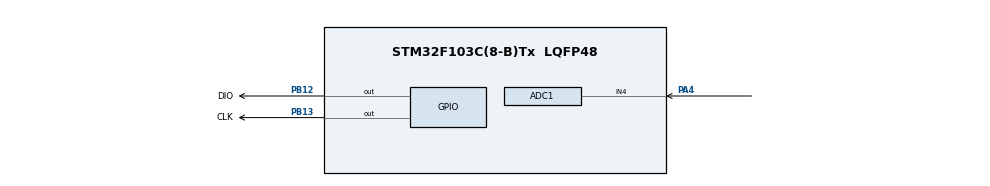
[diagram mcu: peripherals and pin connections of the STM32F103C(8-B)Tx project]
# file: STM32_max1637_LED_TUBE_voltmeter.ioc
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ADC1.Channel-12\#ChannelRegularConversion=ADC_CHANNEL_4
ADC1.NbrOfConversionFlag=1
ADC1.Rank-12\#ChannelRegularConversion=1
ADC1.SamplingTime-12\#ChannelRegularConversion=ADC_SAMPLETIME_1CYCLE_5
ADC1.master=1
Mcu.Family=STM32F1
Mcu.Name=STM32F103C(8-B)Tx
Mcu.Package=LQFP48
NVIC.PriorityGroup=NVIC_PRIORITYGROUP_4
PA13.Mode=Serial_Wire
PA13.Signal=SYS_JTMS-SWDIO
PA14.Mode=Serial_Wire
PA14.Signal=SYS_JTCK-SWCLK
PA4.Signal=ADCx_IN4
PB12.GPIO_Label=DIO
PB12.Signal=GPIO_Output
PB13.GPIO_Label=CLK
PB13.Signal=GPIO_Output
ProjectManager.HeapSize=0x200
ProjectManager.StackSize=0x400
ProjectManager.TargetToolchain=Makefile
RCC.APB1CLKDivider=RCC_HCLK_DIV4
RCC.APB1Freq_Value=2000000
RCC.APB1TimFreq_Value=4000000
RCC.APB2Freq_Value=8000000
RCC.APB2TimFreq_Value=8000000
SH.ADCx_IN4.0=ADC1_IN4,IN4

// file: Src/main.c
/**
  ******************************************************************************
  * File Name          : main.c
  * Description        : Main program body
  ******************************************************************************
  ** This notice applies to any and all portions of this file
  * that are not between comment pairs USER CODE BEGIN and
  * USER CODE END. Other portions of this file, whether
  * inserted by the user or by software development tools
  * are owned by their respective copyright owners.
  *
  * COPYRIGHT(c) 2017 STMicroelectronics
  *
  * Redistribution and use in source and binary forms, with or without modification,
  * are permitted provided that the following conditions are met:
  *   1. Redistributions of source code must retain the above copyright notice,
  *      this list of conditions and the following disclaimer.
  *   2. Redistributions in binary form must reproduce the above copyright notice,
  *      this list of conditions and the following disclaimer in the documentation
  *      and/or other materials provided with the distribution.
  *   3. Neither the name of STMicroelectronics nor the names of its contributors
  *      may be used to endorse or promote products derived from this software
  *      without specific prior written permission.
  *
  * THIS SOFTWARE IS PROVIDED BY THE COPYRIGHT HOLDERS AND CONTRIBUTORS "AS IS"
  * AND ANY EXPRESS OR IMPLIED WARRANTIES, INCLUDING, BUT NOT LIMITED TO, THE
  * IMPLIED WARRANTIES OF MERCHANTABILITY AND FITNESS FOR A PARTICULAR PURPOSE ARE
  * DISCLAIMED. IN NO EVENT SHALL THE COPYRIGHT HOLDER OR CONTRIBUTORS BE LIABLE
  * FOR ANY DIRECT, INDIRECT, INCIDENTAL, SPECIAL, EXEMPLARY, OR CONSEQUENTIAL
  * DAMAGES (INCLUDING, BUT NOT LIMITED TO, PROCUREMENT OF SUBSTITUTE GOODS OR
  * SERVICES; LOSS OF USE, DATA, OR PROFITS; OR BUSINESS INTERRUPTION) HOWEVER
  * CAUSED AND ON ANY THEORY OF LIABILITY, WHETHER IN CONTRACT, STRICT LIABILITY,
  * OR TORT (INCLUDING NEGLIGENCE OR OTHERWISE) ARISING IN ANY WAY OUT OF THE USE
  * OF THIS SOFTWARE, EVEN IF ADVISED OF THE POSSIBILITY OF SUCH DAMAGE.
  *
  ******************************************************************************
  */
#include "main.h"
#include "stm32f1xx_hal.h"

/* USER CODE BEGIN Includes */
#include "1637.h"
#include "main.h"

#define PORT GPIOB
// #define DIO_Pin GPIO_PIN_12
// #define CLK_Pin GPIO_PIN_13

/* USER CODE END Includes */

ADC_HandleTypeDef hadc1;

/* USER CODE BEGIN PV */
/* Private variables ---------------------------------------------------------*/
uint32_t adcResult = 0;
long num;
uint8_t adc_counter;
long display;
/* USER CODE END PV */

void SystemClock_Config(void);
static void MX_GPIO_Init(void);
static void MX_ADC1_Init(void);

/* USER CODE BEGIN PFP */
/* Private function prototypes -----------------------------------------------*/

/* USER CODE END PFP */

int main(void)
{

  /* MCU Configuration----------------------------------------------------------*/

  /* Reset of all peripherals, Initializes the Flash interface and the Systick. */
  HAL_Init();

  /* Configure the system clock */
  SystemClock_Config();

  /* Initialize all configured peripherals */
  MX_GPIO_Init();
  MX_ADC1_Init();

  /* Infinite loop */
  while (1)
  {

  /* USER CODE BEGIN 3 */
    HAL_ADC_Start(&hadc1);
    HAL_ADC_PollForConversion(&hadc1, 100);
    adcResult += HAL_ADC_GetValue(&hadc1);
    adc_counter++; // Увеличиваем счетчик измерений
    if(adc_counter > 5) // Если количество измерений больше N
    {
      display = adcResult/adc_counter/1.246; // Вычисляем среднее значение
      adc_counter = 0; // Обнуляем счетчик измерений
      adcResult = 0; // Обнуляем значение
      HAL_ADC_Stop(&hadc1);
    }
    indication(display);
    HAL_Delay(20);
  }
  /* USER CODE END 3 */

}

/** System Clock Configuration
*/
void SystemClock_Config(void)
{

  RCC_OscInitTypeDef RCC_OscInitStruct;
  RCC_ClkInitTypeDef RCC_ClkInitStruct;
  RCC_PeriphCLKInitTypeDef PeriphClkInit;

    /**Initializes the CPU, AHB and APB busses clocks
    */
  RCC_OscInitStruct.OscillatorType = RCC_OSCILLATORTYPE_HSI;
  RCC_OscInitStruct.HSIState = RCC_HSI_ON;
  RCC_OscInitStruct.HSICalibrationValue = 16;
  RCC_OscInitStruct.PLL.PLLState = RCC_PLL_NONE;
  if (HAL_RCC_OscConfig(&RCC_OscInitStruct) != HAL_OK)
  {
    _Error_Handler(__FILE__, __LINE__);
  }

    /**Initializes the CPU, AHB and APB busses clocks
    */
  RCC_ClkInitStruct.ClockType = RCC_CLOCKTYPE_HCLK|RCC_CLOCKTYPE_SYSCLK
                              |RCC_CLOCKTYPE_PCLK1|RCC_CLOCKTYPE_PCLK2;
  RCC_ClkInitStruct.SYSCLKSource = RCC_SYSCLKSOURCE_HSI;
  RCC_ClkInitStruct.AHBCLKDivider = RCC_SYSCLK_DIV1;
  RCC_ClkInitStruct.APB1CLKDivider = RCC_HCLK_DIV4;
  RCC_ClkInitStruct.APB2CLKDivider = RCC_HCLK_DIV1;

  if (HAL_RCC_ClockConfig(&RCC_ClkInitStruct, FLASH_LATENCY_0) != HAL_OK)
  {
    _Error_Handler(__FILE__, __LINE__);
  }

  PeriphClkInit.PeriphClockSelection = RCC_PERIPHCLK_ADC;
  PeriphClkInit.AdcClockSelection = RCC_ADCPCLK2_DIV2;
  if (HAL_RCCEx_PeriphCLKConfig(&PeriphClkInit) != HAL_OK)
  {
    _Error_Handler(__FILE__, __LINE__);
  }

    /**Configure the Systick interrupt time
    */
  HAL_SYSTICK_Config(HAL_RCC_GetHCLKFreq()/1000);

    /**Configure the Systick
    */
  HAL_SYSTICK_CLKSourceConfig(SYSTICK_CLKSOURCE_HCLK);

  /* SysTick_IRQn interrupt configuration */
  HAL_NVIC_SetPriority(SysTick_IRQn, 0, 0);
}

/* ADC1 init function */
static void MX_ADC1_Init(void)
{

  ADC_ChannelConfTypeDef sConfig;

    /**Common config
    */
  hadc1.Instance = ADC1;
  hadc1.Init.ScanConvMode = ADC_SCAN_DISABLE;
  hadc1.Init.ContinuousConvMode = DISABLE;
  hadc1.Init.DiscontinuousConvMode = DISABLE;
  hadc1.Init.ExternalTrigConv = ADC_SOFTWARE_START;
  hadc1.Init.DataAlign = ADC_DATAALIGN_RIGHT;
  hadc1.Init.NbrOfConversion = 1;
  if (HAL_ADC_Init(&hadc1) != HAL_OK)
  {
    _Error_Handler(__FILE__, __LINE__);
  }

    /**Configure Regular Channel
    */
  sConfig.Channel = ADC_CHANNEL_4;
  sConfig.Rank = 1;
  sConfig.SamplingTime = ADC_SAMPLETIME_1CYCLE_5;
  if (HAL_ADC_ConfigChannel(&hadc1, &sConfig) != HAL_OK)
  {
    _Error_Handler(__FILE__, __LINE__);
  }

}

/** Configure pins as
        * Analog
        * Input
        * Output
        * EVENT_OUT
        * EXTI
*/
static void MX_GPIO_Init(void)
{

  GPIO_InitTypeDef GPIO_InitStruct;

  /* GPIO Ports Clock Enable */
  __HAL_RCC_GPIOA_CLK_ENABLE();
  __HAL_RCC_GPIOB_CLK_ENABLE();

  /*Configure GPIO pin Output Level */
  HAL_GPIO_WritePin(GPIOB, DIO_Pin|CLK_Pin, GPIO_PIN_RESET);

  /*Configure GPIO pins : DIO_Pin CLK_Pin */
  GPIO_InitStruct.Pin = DIO_Pin|CLK_Pin;
  GPIO_InitStruct.Mode = GPIO_MODE_OUTPUT_PP;
  GPIO_InitStruct.Speed = GPIO_SPEED_FREQ_LOW;
  HAL_GPIO_Init(GPIOB, &GPIO_InitStruct);

}

void _Error_Handler(char * file, int line)
{
  while(1)
  {
  }
}

/************************ (C) COPYRIGHT STMicroelectronics *****END OF FILE****/
